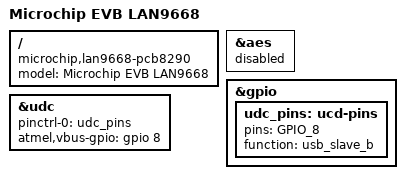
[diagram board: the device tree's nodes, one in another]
// SPDX-License-Identifier: (GPL-2.0+ OR MIT)
/*
 * lan966x-pcb8290.dts - Device Tree file for LAN966X-PCB8290 board
 *
 * Copyright (C) 2022 Microchip Technology Inc. and its subsidiaries
 *
 * Author: Horatiu Vultur <horatiu.vultur@microchip.com>
 */
/dts-v1/;
#include "lan966x.dtsi"

/ {
	model = "Microchip EVB LAN9668";
	compatible = "microchip,lan9668-pcb8290", "microchip,lan9668", "microchip,lan966";
};

&aes {
	status = "disabled"; /* Reserved by secure OS */
};

&gpio {
	udc_pins: ucd-pins {
		/* VBUS_DET B */
		pins = "GPIO_8";
		function = "usb_slave_b";
	};
};

&udc {
	pinctrl-0 = <&udc_pins>;
	pinctrl-names = "default";
	atmel,vbus-gpio = <&gpio 8 GPIO_ACTIVE_HIGH>;
	status = "okay";
};
